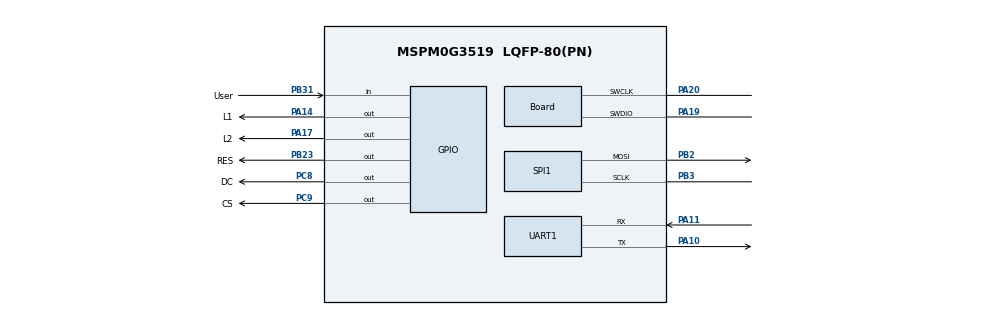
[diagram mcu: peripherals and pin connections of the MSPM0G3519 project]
/**
 * AI AGENTS: Do not edit this file directly. There is no validation or error feedback when
 * editing manually — mistakes will be silent until the file is loaded in SysConfig.
 * Use the SysConfig MCP server instead to make changes with immediate error reporting.
 *
 * These arguments were used when this file was generated. They will be automatically applied on subsequent loads
 * via the GUI or CLI. Run CLI with '--help' for additional information on how to override these arguments.
 * @cliArgs --device "MSPM0G351X" --part "Default" --package "LQFP-80(PN)" --product "mspm0_sdk@2.10.00.04"
 * @v2CliArgs --device "MSPM0G3519" --package "LQFP-80(PN)" --product "mspm0_sdk@2.10.00.04"
 * @versions {"tool":"1.28.0+4712"}
 */

/**
 * Import the modules used in this configuration.
 */
const GPIO   = scripting.addModule("/ti/driverlib/GPIO", {}, false);
const GPIO1  = GPIO.addInstance();
const GPIO2  = GPIO.addInstance();
const GPIO3  = GPIO.addInstance();
const SYSCTL = scripting.addModule("/ti/driverlib/SYSCTL");
const SPI    = scripting.addModule("/ti/driverlib/SPI", {}, false);
const SPI1   = SPI.addInstance();
const UART   = scripting.addModule("/ti/driverlib/UART", {}, false);
const UART1  = UART.addInstance();

/**
 * Clock Tree: SYSOSC(32MHz) * 5 / 1 = 160MHz VCO, UDIV/2 = 80MHz MCLK
 */
const divider9       = system.clockTree["UDIV"];
divider9.divideValue = 2;

const multiplier2         = system.clockTree["PLL_QDIV"];
multiplier2.multiplyValue = 5;

const mux8       = system.clockTree["HSCLKMUX"];
mux8.inputSelect = "HSCLKMUX_SYSPLL0";

const mux10       = system.clockTree["MFPCLKMUX"];
mux10.inputSelect = "MFPCLKMUX_HFCLK";

const mux12       = system.clockTree["SYSPLLMUX"];
mux12.inputSelect = "SYSPLLMUX_SYSOSC";

SYSCTL.clockTreeEn = true;

/**
 * GPIO
 */
GPIO1.$name                              = "LED";
GPIO1.associatedPins.create(2);
GPIO1.associatedPins[0].$name            = "L2";
GPIO1.associatedPins[0].internalResistor = "PULL_UP";
GPIO1.associatedPins[0].pin.$assign      = "PA17";
GPIO1.associatedPins[1].$name            = "L1";
GPIO1.associatedPins[1].internalResistor = "PULL_UP";
GPIO1.associatedPins[1].pin.$assign      = "PA14";

GPIO2.$name                              = "Key";
GPIO2.associatedPins[0].$name            = "User";
GPIO2.associatedPins[0].direction        = "INPUT";
GPIO2.associatedPins[0].internalResistor = "PULL_UP";
GPIO2.associatedPins[0].pin.$assign      = "PB31";

GPIO3.$name                              = "OLED";
GPIO3.associatedPins.create(3);
GPIO3.associatedPins[0].$name            = "RES";
GPIO3.associatedPins[0].pin.$assign      = "PB23";
GPIO3.associatedPins[1].$name            = "DC";
GPIO3.associatedPins[1].pin.$assign      = "PC8";
GPIO3.associatedPins[2].$name            = "CS";
GPIO3.associatedPins[2].internalResistor = "PULL_UP";
GPIO3.associatedPins[2].pin.$assign      = "PC9";

const Board                       = scripting.addModule("/ti/driverlib/Board", {}, false);
Board.peripheral.$assign          = "DEBUGSS";
Board.peripheral.swclkPin.$assign = "PA20";
Board.peripheral.swdioPin.$assign = "PA19";

/**
 * SPI0: MOTO3 (CPOL=1,CPHA=1), SCK=PB3, MOSI=PB2
 */
SPI1.$name                      = "SPI_0";
SPI1.frameFormat                = "MOTO3";
SPI1.direction                  = "PICO";
SPI1.polarity                   = "1";
SPI1.phase                      = "1";
SPI1.sclkPinConfig.$name        = "ti_driverlib_gpio_GPIOPinGeneric4";
SPI1.mosiPinConfig.$name        = "ti_driverlib_gpio_GPIOPinGeneric5";
SPI1.peripheral.sclkPin.$assign = "PB3";
SPI1.peripheral.mosiPin.$assign = "PB2";

/**
 * UART0: RX=PA11, TX=PA10, 9600 baud
 */
UART1.$name                    = "UART_0";
UART1.enabledInterrupts        = ["RX"];
UART1.peripheral.rxPin.$assign = "PA11";
UART1.peripheral.txPin.$assign = "PA10";
UART1.txPinConfig.$name        = "ti_driverlib_gpio_GPIOPinGeneric0";
UART1.rxPinConfig.$name        = "ti_driverlib_gpio_GPIOPinGeneric1";

const ProjectConfig              = scripting.addModule("/ti/project_config/ProjectConfig", {}, false);
ProjectConfig.migrationCondition = true;

/**
 * Pinmux solution for unlocked pins/peripherals.
 */
SPI1.peripheral.$suggestSolution  = "SPI0";
UART1.peripheral.$suggestSolution = "UART0";
